# ATSAMV70J20 register map
Vendor: Microchip Technology; File version: 0
CPU: CM7 r1p1, little endian, no MPU, no FPU, 0x3 interrupt priority bits, 0x0 interrupts
Registers are 32-bit, read-write, reset 0x0 unless marked. A register's access mark holds for its fields unless they carry their own. Offsets are from the block's base; [hi:lo] are bit positions; 'fields as' and 'values as' point back to an identical list.

## RSTC — Reset Controller
Base 0x400E1800; register names take the prefix RSTC_
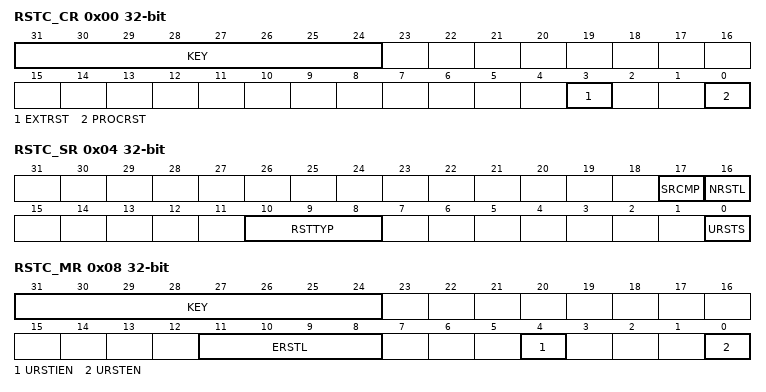
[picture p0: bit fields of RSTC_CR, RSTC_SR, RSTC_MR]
0x00 RSTC_CR wo — Control Register
  [31:24] KEY — System Reset Key
    165=PASSWD (Writing any other value in this field aborts the write operation.)
  [3] EXTRST — External Reset
  [0] PROCRST — Processor Reset
0x04 RSTC_SR ro — Status Register
  [17] SRCMP — Software Reset Command in Progress
  [16] NRSTL — NRST Pin Level
  [10:8] RSTTYP — Reset Type
    0=GENERAL_RST (First powerup reset); 1=BACKUP_RST (Return from Backup mode); 2=WDT_RST (Watchdog fault occurred); 3=SOFT_RST (Processor reset required by the software); 4=USER_RST (NRST pin detected low)
  [0] URSTS — User Reset Status
0x08 RSTC_MR — Mode Register
  [31:24] KEY — Write Access Password
    165=PASSWD (Writing any other value in this field aborts the write operation.Always reads as 0.)
  [11:8] ERSTL — External Reset Length
  [4] URSTIEN — User Reset Interrupt Enable
  [0] URSTEN — User Reset Enable

## RSWDT — Reinforced Safety Watchdog Timer
Base 0x400E1900; register names take the prefix RSWDT_
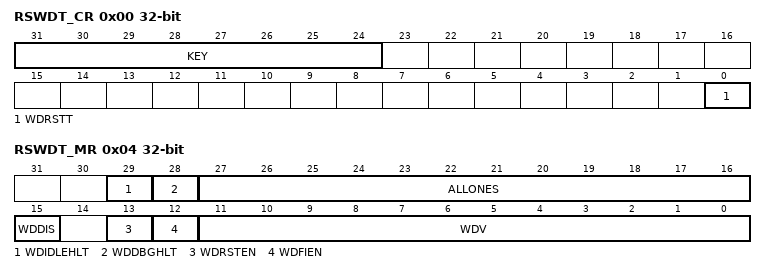
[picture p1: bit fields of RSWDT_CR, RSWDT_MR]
0x00 RSWDT_CR wo — Control Register
  [31:24] KEY — Password
    196=PASSWD (Writing any other value in this field aborts the write operation.)
  [0] WDRSTT — Watchdog Restart
0x04 RSWDT_MR — Mode Register
  [29] WDIDLEHLT — Watchdog Idle Halt
  [28] WDDBGHLT — Watchdog Debug Halt
  [27:16] ALLONES — Must Always Be Written with 0xFFF
  [15] WDDIS — Watchdog Disable
  [13] WDRSTEN — Watchdog Reset Enable
  [12] WDFIEN — Watchdog Fault Interrupt Enable
  [11:0] WDV — Watchdog Counter Value
0x08 RSWDT_SR ro — Status Register
  [0] WDUNF — Watchdog Underflow

## RTT — Real-time Timer
Base 0x400E1830; register names take the prefix RTT_
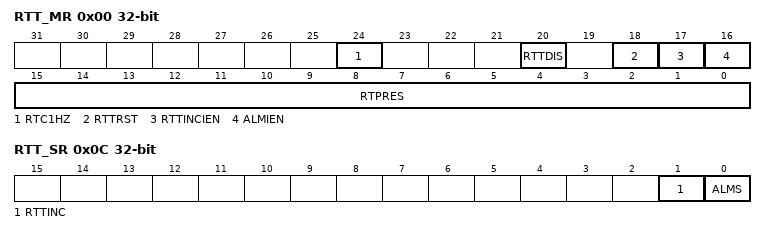
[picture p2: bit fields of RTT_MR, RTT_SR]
0x00 RTT_MR — Mode Register
  [24] RTC1HZ — Real-Time Clock 1Hz Clock Selection
  [20] RTTDIS — Real-time Timer Disable
  [18] RTTRST — Real-time Timer Restart
  [17] RTTINCIEN — Real-time Timer Increment Interrupt Enable
  [16] ALMIEN — Alarm Interrupt Enable
  [15:0] RTPRES — Real-time Timer Prescaler Value
0x04 RTT_AR — Alarm Register
  [31:0] ALMV — Alarm Value
0x08 RTT_VR ro — Value Register
  [31:0] CRTV — Current Real-time Value
0x0C RTT_SR ro — Status Register
  [1] RTTINC — Prescaler Roll-over Status (cleared on read)
  [0] ALMS — Real-time Alarm Status (cleared on read)

## TC0 — Timer Counter
Base 0x4000C000; register names take the prefix TC_
0xC0 TC_BCR wo — Block Control Register
  [0] SYNC — Synchro Command
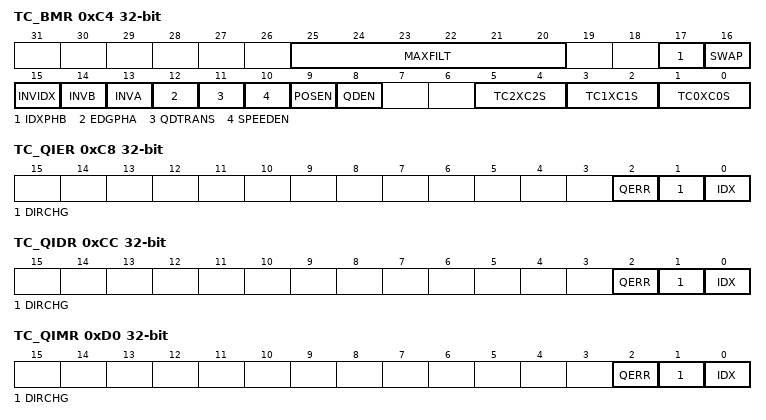
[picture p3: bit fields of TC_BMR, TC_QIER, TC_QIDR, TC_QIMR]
0xC4 TC_BMR — Block Mode Register
  [25:20] MAXFILT — Maximum Filter
  [17] IDXPHB — Index Pin is PHB Pin
  [16] SWAP — Swap PHA and PHB
  [15] INVIDX — Inverted Index
  [14] INVB — Inverted PHB
  [13] INVA — Inverted PHA
  [12] EDGPHA — Edge on PHA Count Mode
  [11] QDTRANS — Quadrature Decoding Transparent
  [10] SPEEDEN — Speed Enabled
  [9] POSEN — Position Enabled
  [8] QDEN — Quadrature Decoder Enabled
  [5:4] TC2XC2S — External Clock Signal 2 Selection
    0=TCLK2 (Signal connected to XC2: TCLK2); 2=TIOA0 (Signal connected to XC2: TIOA0); 3=TIOA1 (Signal connected to XC2: TIOA1)
  [3:2] TC1XC1S — External Clock Signal 1 Selection
    0=TCLK1 (Signal connected to XC1: TCLK1); 2=TIOA0 (Signal connected to XC1: TIOA0); 3=TIOA2 (Signal connected to XC1: TIOA2)
  [1:0] TC0XC0S — External Clock Signal 0 Selection
    0=TCLK0 (Signal connected to XC0: TCLK0); 2=TIOA1 (Signal connected to XC0: TIOA1); 3=TIOA2 (Signal connected to XC0: TIOA2)
0xC8 TC_QIER wo — QDEC Interrupt Enable Register
  [2] QERR — Quadrature Error
  [1] DIRCHG — Direction Change
  [0] IDX — Index
0xCC TC_QIDR wo — QDEC Interrupt Disable Register
  fields as TC_QIER
0xD0 TC_QIMR ro — QDEC Interrupt Mask Register
  fields as TC_QIER
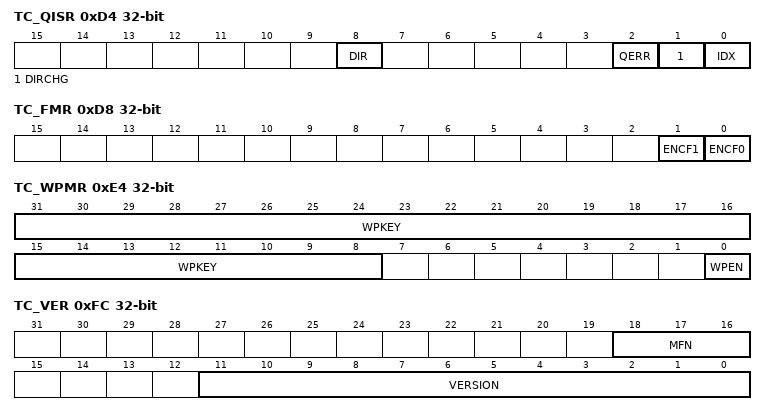
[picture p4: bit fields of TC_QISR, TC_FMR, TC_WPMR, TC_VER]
0xD4 TC_QISR ro — QDEC Interrupt Status Register
  [8] DIR — Direction
  [2] QERR — Quadrature Error
  [1] DIRCHG — Direction Change
  [0] IDX — Index
0xD8 TC_FMR — Fault Mode Register
  [1] ENCF1 — Enable Compare Fault Channel 1
  [0] ENCF0 — Enable Compare Fault Channel 0
0xE4 TC_WPMR — Write Protection Mode Register
  [31:8] WPKEY — Write Protection Key
    0x54494D=PASSWD (Writing any other value in this field aborts the write operation of the WPEN bit.Always reads as 0.)
  [0] WPEN — Write Protection Enable
0xFC TC_VER ro — Version Register
  [18:16] MFN — Metal Fix Number
  [11:0] VERSION — Version of the Hardware Module

## TC1 — Timer Counter
Base 0x40010000; register names take the prefix TC_
Registers as TC0; these are added or differ:
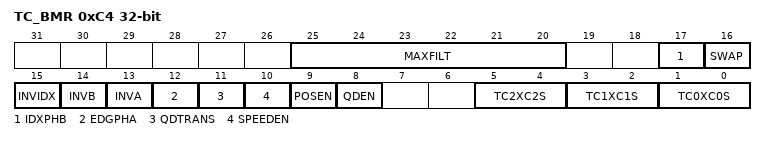
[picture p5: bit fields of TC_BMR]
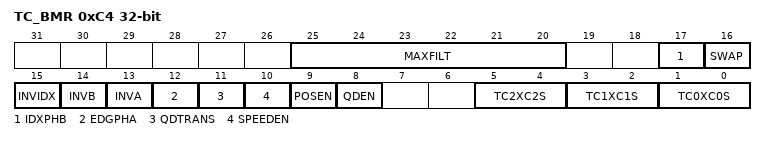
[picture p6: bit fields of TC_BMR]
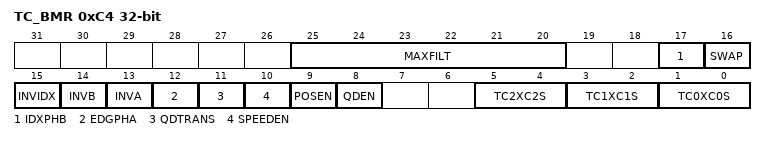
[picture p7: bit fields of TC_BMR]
0xC4 TC_BMR — Block Mode Register
  fields as TC0.TC_BMR

## TC2 — Timer Counter
Base 0x40014000; register names take the prefix TC_
Registers as TC0; these are added or differ:
0xC4 TC_BMR — Block Mode Register
  fields as TC0.TC_BMR

## TC3 — Timer Counter
Base 0x40054000; register names take the prefix TC_
Registers as TC0; these are added or differ:
0xC4 TC_BMR — Block Mode Register
  fields as TC0.TC_BMR
